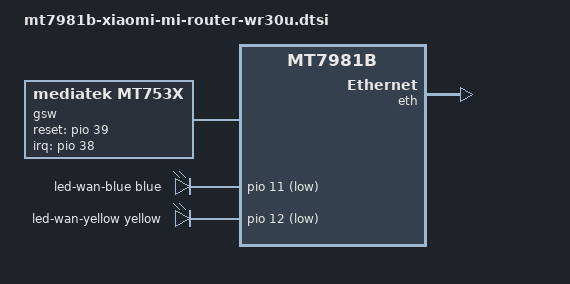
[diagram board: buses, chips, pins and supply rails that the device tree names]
// SPDX-License-Identifier: GPL-2.0-or-later OR MIT

/dts-v1/;
#include "mt7981b-xiaomi-mi-router-common.dtsi"

/ {
	gsw: gsw@0 {
		compatible = "mediatek,mt753x";
		mediatek,ethsys = <&ethsys>;
		#address-cells = <1>;
		#size-cells = <0>;
	};
};

&eth {
	status = "okay";

	gmac0: mac@0 {
		compatible = "mediatek,eth-mac";
		reg = <0>;
		phy-mode = "2500base-x";
		nvmem-cell-names = "mac-address";
		nvmem-cells = <&macaddr_factory_4 (-1)>;

		fixed-link {
			speed = <2500>;
			full-duplex;
			pause;
		};
	};

	gmac1: mac@1 {
		compatible = "mediatek,eth-mac";
		reg = <1>;
		phy-mode = "2500base-x";
		nvmem-cell-names = "mac-address";
		nvmem-cells = <&macaddr_factory_4 (-2)>;

		fixed-link {
			speed = <2500>;
			full-duplex;
			pause;
		};
	};

	mdio: mdio-bus {
		#address-cells = <1>;
		#size-cells = <0>;
		/delete-node/ ethernet-phy@0;
		/delete-node/ switch@1f;
		/delete-node/ mfd@1;
	};
};

&gsw {
	mediatek,mdio = <&mdio>;
	mediatek,mdio_master_pinmux = <0>;
	reset-gpios = <&pio 39 0>;
	interrupt-parent = <&pio>;
	interrupts = <38 IRQ_TYPE_LEVEL_HIGH>;
	status = "okay";

	port5: port@5 {
		compatible = "mediatek,mt753x-port";
		mediatek,ssc-on;
		reg = <5>;
		phy-mode = "sgmii";

		fixed-link {
			speed = <2500>;
			full-duplex;
		};
	};

	port6: port@6 {
		compatible = "mediatek,mt753x-port";
		mediatek,ssc-on;
		reg = <6>;
		phy-mode = "sgmii";

		fixed-link {
			speed = <2500>;
			full-duplex;
		};
	};
};

&leds {
	led-wan-blue {
		color = <LED_COLOR_ID_BLUE>;
		function = LED_FUNCTION_WAN;
		gpios = <&pio 11 GPIO_ACTIVE_LOW>;
	};

	led-wan-yellow {
		color = <LED_COLOR_ID_YELLOW>;
		function = LED_FUNCTION_WAN;
		gpios = <&pio 12 GPIO_ACTIVE_LOW>;
	};
};
